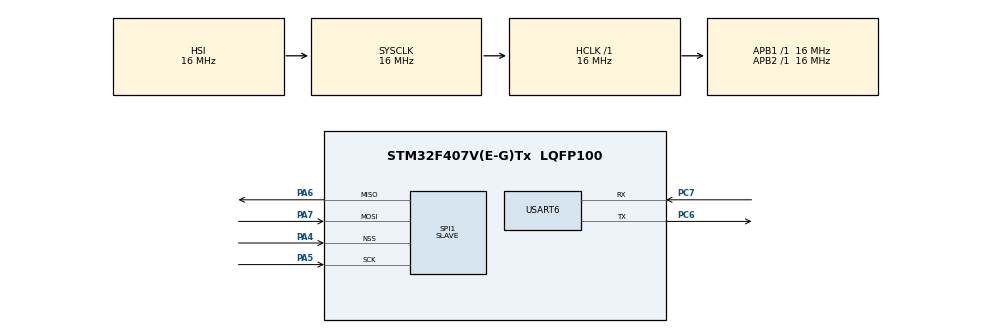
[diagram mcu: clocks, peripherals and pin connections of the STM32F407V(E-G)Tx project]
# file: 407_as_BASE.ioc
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Mcu.Family=STM32F4
Mcu.Name=STM32F407V(E-G)Tx
Mcu.Package=LQFP100
NVIC.PriorityGroup=NVIC_PRIORITYGROUP_4
NVIC.USART6_IRQn=true\:0\:0\:false\:false\:true\:true\:true
PA13.Mode=Serial_Wire
PA13.Signal=SYS_JTMS-SWDIO
PA14.Mode=Serial_Wire
PA14.Signal=SYS_JTCK-SWCLK
PA4.Mode=NSS_Signal_Hard_Input
PA4.Signal=SPI1_NSS
PA5.GPIO_PuPd=GPIO_PULLUP
PA5.Mode=Full_Duplex_Slave
PA5.Signal=SPI1_SCK
PA6.Mode=Full_Duplex_Slave
PA6.Signal=SPI1_MISO
PA7.GPIO_PuPd=GPIO_PULLUP
PA7.Mode=Full_Duplex_Slave
PA7.Signal=SPI1_MOSI
PC6.Mode=Asynchronous
PC6.Signal=USART6_TX
PC7.Mode=Asynchronous
PC7.Signal=USART6_RX
ProjectManager.HeapSize=0x200
ProjectManager.StackSize=0x400
ProjectManager.TargetToolchain=STM32CubeIDE
RCC.AHBFreq_Value=16000000
RCC.APB1Freq_Value=16000000
RCC.APB2Freq_Value=16000000
RCC.CortexFreq_Value=16000000
RCC.HSE_VALUE=25000000
RCC.HSI_VALUE=16000000
RCC.LSE_VALUE=32768
RCC.SYSCLKFreq_VALUE=16000000
RCC.VCOOutputFreq_Value=192000000
SPI1.CLKPolarity=SPI_POLARITY_HIGH
SPI1.CRCCalculation=SPI_CRCCALCULATION_DISABLE
SPI1.Direction=SPI_DIRECTION_2LINES
SPI1.Mode=SPI_MODE_SLAVE
SPI1.TIMode=SPI_TIMODE_DISABLE
SPI1.VirtualNSS=VM_NSSHARD
SPI1.VirtualType=VM_SLAVE
USART6.VirtualMode=VM_ASYNC
board=custom

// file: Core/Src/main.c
/* USER CODE BEGIN Header */
/**
  ******************************************************************************
  * @file           : main.c
  * @brief          : Main program body
  ******************************************************************************
  * @attention
  *
  * Copyright (c) 2023 STMicroelectronics.
  * All rights reserved.
  *
  * This software is licensed under terms that can be found in the LICENSE file
  * in the root directory of this software component.
  * If no LICENSE file comes with this software, it is provided AS-IS.
  *
  ******************************************************************************
  */
/* USER CODE END Header */
#include "main.h"

/* USER CODE BEGIN PM */
#define USART_BUFF_SIZE 1024
/* USER CODE END PM */

SPI_HandleTypeDef hspi1;

UART_HandleTypeDef huart6;

void SystemClock_Config(void);
static void MX_GPIO_Init(void);
static void MX_USART6_UART_Init(void);
static void MX_SPI1_Init(void);

/* USER CODE BEGIN 0 */
void HAL_UART_TxCpltCallback(UART_HandleTypeDef *huart)
{
   if(huart->Instance == USART6)
   {

//        flagUSARTSend = 1;
   }

}
/* USER CODE END 0 */

int main(void)
{

  /* MCU Configuration--------------------------------------------------------*/

  /* Reset of all peripherals, Initializes the Flash interface and the Systick. */
  HAL_Init();

  /* Configure the system clock */
  SystemClock_Config();

  /* Initialize all configured peripherals */
  MX_GPIO_Init();
  MX_USART6_UART_Init();
  MX_SPI1_Init();

  /* Infinite loop */
  /* USER CODE BEGIN WHILE */
  char timeString[12];
HAL_UART_Transmit(&huart6,(uint8_t*)"Test_UART\r\n", sizeof ("Test_UART\r\n") -1 , 1000);
  while (1)
  {
      char tmp[USART_BUFF_SIZE]="";
      char toUSART[USART_BUFF_SIZE]="";
//      char bufSPI[16]="";
//      while (HAL_GPIO_ReadPin(GPIOA, GPIO_PIN_4) == GPIO_PIN_SET ){} //Ожидаем PSI_SS
      HAL_StatusTypeDef result =  HAL_SPI_Receive(&hspi1,(uint8_t*)tmp, USART_BUFF_SIZE, 0x100);
      if (result == HAL_OK)
      {
            strncpy(toUSART, tmp, USART_BUFF_SIZE);
            HAL_UART_Transmit_IT(&huart6,(uint8_t*)toUSART, USART_BUFF_SIZE);
            while( HAL_UART_GetState (&huart6) == HAL_UART_STATE_BUSY_TX ) ;
      }

//      uint32_t time = HAL_GetTick();
//      sprintf(timeString,"%.9d\r\n",time);
//      HAL_UART_Transmit(&huart6,(uint8_t*)timeString, sizeof(timeString)-1  , 1000);
//      HAL_Delay(time%2000);
    /* USER CODE END WHILE */

  }
}

void SystemClock_Config(void)
{
  RCC_OscInitTypeDef RCC_OscInitStruct = {0};
  RCC_ClkInitTypeDef RCC_ClkInitStruct = {0};

  /** Configure the main internal regulator output voltage
  */
  __HAL_RCC_PWR_CLK_ENABLE();
  __HAL_PWR_VOLTAGESCALING_CONFIG(PWR_REGULATOR_VOLTAGE_SCALE1);
  /** Initializes the RCC Oscillators according to the specified parameters
  * in the RCC_OscInitTypeDef structure.
  */
  RCC_OscInitStruct.OscillatorType = RCC_OSCILLATORTYPE_HSI;
  RCC_OscInitStruct.HSIState = RCC_HSI_ON;
  RCC_OscInitStruct.HSICalibrationValue = RCC_HSICALIBRATION_DEFAULT;
  RCC_OscInitStruct.PLL.PLLState = RCC_PLL_NONE;
  if (HAL_RCC_OscConfig(&RCC_OscInitStruct) != HAL_OK)
  {
    Error_Handler();
  }
  /** Initializes the CPU, AHB and APB buses clocks
  */
  RCC_ClkInitStruct.ClockType = RCC_CLOCKTYPE_HCLK|RCC_CLOCKTYPE_SYSCLK
                              |RCC_CLOCKTYPE_PCLK1|RCC_CLOCKTYPE_PCLK2;
  RCC_ClkInitStruct.SYSCLKSource = RCC_SYSCLKSOURCE_HSI;
  RCC_ClkInitStruct.AHBCLKDivider = RCC_SYSCLK_DIV1;
  RCC_ClkInitStruct.APB1CLKDivider = RCC_HCLK_DIV1;
  RCC_ClkInitStruct.APB2CLKDivider = RCC_HCLK_DIV1;

  if (HAL_RCC_ClockConfig(&RCC_ClkInitStruct, FLASH_LATENCY_0) != HAL_OK)
  {
    Error_Handler();
  }
}

static void MX_SPI1_Init(void)
{

  /* SPI1 parameter configuration*/
  hspi1.Instance = SPI1;
  hspi1.Init.Mode = SPI_MODE_SLAVE;
  hspi1.Init.Direction = SPI_DIRECTION_2LINES;
  hspi1.Init.DataSize = SPI_DATASIZE_8BIT;
  hspi1.Init.CLKPolarity = SPI_POLARITY_HIGH;
  hspi1.Init.CLKPhase = SPI_PHASE_1EDGE;
  hspi1.Init.NSS = SPI_NSS_HARD_INPUT;
  hspi1.Init.FirstBit = SPI_FIRSTBIT_MSB;
  hspi1.Init.TIMode = SPI_TIMODE_DISABLE;
  hspi1.Init.CRCCalculation = SPI_CRCCALCULATION_DISABLE;
  hspi1.Init.CRCPolynomial = 10;
  if (HAL_SPI_Init(&hspi1) != HAL_OK)
  {
    Error_Handler();
  }

}

static void MX_USART6_UART_Init(void)
{

  huart6.Instance = USART6;
  huart6.Init.BaudRate = 115200;
  huart6.Init.WordLength = UART_WORDLENGTH_8B;
  huart6.Init.StopBits = UART_STOPBITS_1;
  huart6.Init.Parity = UART_PARITY_NONE;
  huart6.Init.Mode = UART_MODE_TX_RX;
  huart6.Init.HwFlowCtl = UART_HWCONTROL_NONE;
  huart6.Init.OverSampling = UART_OVERSAMPLING_16;
  if (HAL_UART_Init(&huart6) != HAL_OK)
  {
    Error_Handler();
  }

}

static void MX_GPIO_Init(void)
{

  /* GPIO Ports Clock Enable */
  __HAL_RCC_GPIOA_CLK_ENABLE();
  __HAL_RCC_GPIOC_CLK_ENABLE();

}

void Error_Handler(void)
{
  __disable_irq();
  while (1)
  {
  }
}
